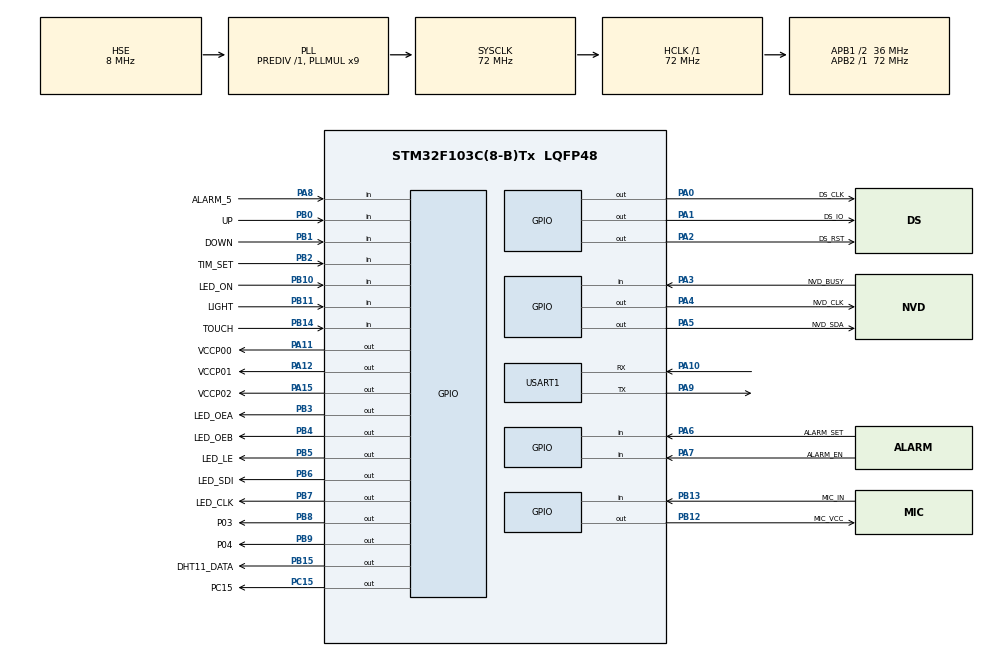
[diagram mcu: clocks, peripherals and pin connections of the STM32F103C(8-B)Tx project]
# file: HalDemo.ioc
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Mcu.Family=STM32F1
Mcu.Name=STM32F103C(8-B)Tx
Mcu.Package=LQFP48
NVIC.PriorityGroup=NVIC_PRIORITYGROUP_4
PA0-WKUP.GPIO_Label=DS_CLK
PA0-WKUP.GPIO_Speed=GPIO_SPEED_FREQ_HIGH
PA0-WKUP.Signal=GPIO_Output
PA1.GPIO_Label=DS_IO
PA1.GPIO_ModeDefaultOutputPP=GPIO_MODE_OUTPUT_OD
PA1.GPIO_PuPd=GPIO_NOPULL
PA1.GPIO_Speed=GPIO_SPEED_FREQ_HIGH
PA1.PinState=GPIO_PIN_SET
PA1.Signal=GPIO_Output
PA10.Mode=Asynchronous
PA10.Signal=USART1_RX
PA11.GPIO_Label=VCCP00
PA11.GPIO_Speed=GPIO_SPEED_FREQ_HIGH
PA11.PinState=GPIO_PIN_SET
PA11.Signal=GPIO_Output
PA12.GPIO_Label=VCCP01
PA12.GPIO_Speed=GPIO_SPEED_FREQ_HIGH
PA12.PinState=GPIO_PIN_SET
PA12.Signal=GPIO_Output
PA13.Mode=Serial_Wire
PA13.Signal=SYS_JTMS-SWDIO
PA14.Mode=Serial_Wire
PA14.Signal=SYS_JTCK-SWCLK
PA15.GPIO_Label=VCCP02
PA15.GPIO_Speed=GPIO_SPEED_FREQ_HIGH
PA15.PinState=GPIO_PIN_SET
PA15.Signal=GPIO_Output
PA2.GPIO_Label=DS_RST
PA2.GPIO_Speed=GPIO_SPEED_FREQ_HIGH
PA2.Signal=GPIO_Output
PA3.GPIO_Label=NVD_BUSY
PA3.GPIO_PuPd=GPIO_PULLUP
PA3.Signal=GPIO_Input
PA4.GPIO_Label=NVD_CLK
PA4.GPIO_PuPd=GPIO_NOPULL
PA4.GPIO_Speed=GPIO_SPEED_FREQ_HIGH
PA4.PinState=GPIO_PIN_SET
PA4.Signal=GPIO_Output
PA5.GPIO_Label=NVD_SDA
PA5.GPIO_Speed=GPIO_SPEED_FREQ_HIGH
PA5.PinState=GPIO_PIN_SET
PA5.Signal=GPIO_Output
PA6.GPIO_Label=ALARM_SET
PA6.GPIO_PuPd=GPIO_PULLUP
PA6.Signal=GPIO_Input
PA7.GPIO_Label=ALARM_EN
PA7.GPIO_PuPd=GPIO_PULLUP
PA7.Signal=GPIO_Input
PA8.GPIO_Label=ALARM_5
PA8.GPIO_PuPd=GPIO_PULLUP
PA8.Signal=GPIO_Input
PA9.Mode=Asynchronous
PA9.Signal=USART1_TX
PB0.GPIO_Label=UP
PB0.GPIO_PuPd=GPIO_PULLUP
PB0.Signal=GPIO_Input
PB1.GPIO_Label=DOWN
PB1.GPIO_PuPd=GPIO_PULLUP
PB1.Signal=GPIO_Input
PB10.GPIO_Label=LED_ON
PB10.GPIO_PuPd=GPIO_PULLUP
PB10.Signal=GPIO_Input
PB11.GPIO_Label=LIGHT
PB11.GPIO_PuPd=GPIO_PULLUP
PB11.Signal=GPIO_Input
PB12.GPIO_Label=MIC_VCC
PB12.PinState=GPIO_PIN_SET
PB12.Signal=GPIO_Output
PB13.GPIO_Label=MIC_IN
PB13.Signal=GPIO_Input
PB14.GPIO_Label=TOUCH
PB14.Signal=GPIO_Input
PB15.GPIO_Label=DHT11_DATA
PB15.GPIO_ModeDefaultOutputPP=GPIO_MODE_OUTPUT_OD
PB15.GPIO_PuPd=GPIO_NOPULL
PB15.GPIO_Speed=GPIO_SPEED_FREQ_HIGH
PB15.PinState=GPIO_PIN_SET
PB15.Signal=GPIO_Output
PB2.GPIO_Label=TIM_SET
PB2.GPIO_PuPd=GPIO_PULLUP
PB2.Signal=GPIO_Input
PB3.GPIO_Label=LED_OEA
PB3.GPIO_Speed=GPIO_SPEED_FREQ_HIGH
PB3.PinState=GPIO_PIN_SET
PB3.Signal=GPIO_Output
PB4.GPIO_Label=LED_OEB
PB4.GPIO_Speed=GPIO_SPEED_FREQ_HIGH
PB4.PinState=GPIO_PIN_SET
PB4.Signal=GPIO_Output
PB5.GPIO_Label=LED_LE
PB5.GPIO_Speed=GPIO_SPEED_FREQ_HIGH
PB5.PinState=GPIO_PIN_SET
PB5.Signal=GPIO_Output
PB6.GPIO_Label=LED_SDI
PB6.GPIO_Speed=GPIO_SPEED_FREQ_HIGH
PB6.PinState=GPIO_PIN_RESET
PB6.Signal=GPIO_Output
PB7.GPIO_Label=LED_CLK
PB7.GPIO_Speed=GPIO_SPEED_FREQ_HIGH
PB7.Signal=GPIO_Output
PB8.GPIO_Label=P03
PB8.GPIO_Speed=GPIO_SPEED_FREQ_HIGH
PB8.PinState=GPIO_PIN_SET
PB8.Signal=GPIO_Output
PB9.GPIO_Label=P04
PB9.GPIO_Speed=GPIO_SPEED_FREQ_HIGH
PB9.PinState=GPIO_PIN_SET
PB9.Signal=GPIO_Output
PC15-OSC32_OUT.GPIO_Label=PC15
PC15-OSC32_OUT.GPIO_Speed=GPIO_SPEED_FREQ_LOW
PC15-OSC32_OUT.PinState=GPIO_PIN_RESET
PC15-OSC32_OUT.Signal=GPIO_Output
PD0-OSC_IN.Mode=HSE-External-Oscillator
PD0-OSC_IN.Signal=RCC_OSC_IN
PD1-OSC_OUT.Mode=HSE-External-Oscillator
PD1-OSC_OUT.Signal=RCC_OSC_OUT
ProjectManager.HeapSize=0x200
ProjectManager.StackSize=0x400
ProjectManager.TargetToolchain=MDK-ARM V5.32
RCC.AHBFreq_Value=72000000
RCC.APB1CLKDivider=RCC_HCLK_DIV2
RCC.APB1Freq_Value=36000000
RCC.APB1TimFreq_Value=72000000
RCC.APB2Freq_Value=72000000
RCC.APB2TimFreq_Value=72000000
RCC.HCLKFreq_Value=72000000
RCC.PLLMUL=RCC_PLL_MUL9
RCC.PLLSourceVirtual=RCC_PLLSOURCE_HSE
RCC.SYSCLKFreq_VALUE=72000000
RCC.SYSCLKSource=RCC_SYSCLKSOURCE_PLLCLK
RCC.USBFreq_Value=72000000
USART1.VirtualMode=VM_ASYNC
board=custom

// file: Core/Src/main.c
/* USER CODE BEGIN Header */
/**
 ******************************************************************************
 * @file           : main.c
 * @brief          : Main program body
 ******************************************************************************
 * @attention
 *
 * Copyright (c) 2026 STMicroelectronics.
 * All rights reserved.
 *
 * This software is licensed under terms that can be found in the LICENSE file
 * in the root directory of this software component.
 * If no LICENSE file comes with this software, it is provided AS-IS.
 *
 ******************************************************************************
 */
/* USER CODE END Header */
#include "main.h"
#include "usart.h"
#include "gpio.h"

/* USER CODE BEGIN Includes */
#include "Com_debug.h"
#include "App_freeRTOS.h"
/* USER CODE END Includes */

void SystemClock_Config(void);

int main(void)
{

  /* MCU Configuration--------------------------------------------------------*/

  /* Reset of all peripherals, Initializes the Flash interface and the Systick. */
  HAL_Init();

  /* Configure the system clock */
  SystemClock_Config();

  /* Initialize all configured peripherals */
  MX_GPIO_Init();
  MX_USART1_UART_Init();
  /* USER CODE BEGIN 2 */
  //*******************************尽量在初始化后写代码************************************//
  // HAL_UART_Transmit(&huart1, "Hello World!\r\n", 14, 1000);

  // freeRTOS的启动函数
  App_freeRTOS_Start();
  /* USER CODE END 2 */

  /* Infinite loop */
  while (1)
  {

  }
}

void SystemClock_Config(void)
{
  RCC_OscInitTypeDef RCC_OscInitStruct = {0};
  RCC_ClkInitTypeDef RCC_ClkInitStruct = {0};

  /** Initializes the RCC Oscillators according to the specified parameters
  * in the RCC_OscInitTypeDef structure.
  */
  RCC_OscInitStruct.OscillatorType = RCC_OSCILLATORTYPE_HSE;
  RCC_OscInitStruct.HSEState = RCC_HSE_ON;
  RCC_OscInitStruct.HSEPredivValue = RCC_HSE_PREDIV_DIV1;
  RCC_OscInitStruct.HSIState = RCC_HSI_ON;
  RCC_OscInitStruct.PLL.PLLState = RCC_PLL_ON;
  RCC_OscInitStruct.PLL.PLLSource = RCC_PLLSOURCE_HSE;
  RCC_OscInitStruct.PLL.PLLMUL = RCC_PLL_MUL9;
  if (HAL_RCC_OscConfig(&RCC_OscInitStruct) != HAL_OK)
  {
    Error_Handler();
  }

  /** Initializes the CPU, AHB and APB buses clocks
  */
  RCC_ClkInitStruct.ClockType = RCC_CLOCKTYPE_HCLK|RCC_CLOCKTYPE_SYSCLK
                              |RCC_CLOCKTYPE_PCLK1|RCC_CLOCKTYPE_PCLK2;
  RCC_ClkInitStruct.SYSCLKSource = RCC_SYSCLKSOURCE_PLLCLK;
  RCC_ClkInitStruct.AHBCLKDivider = RCC_SYSCLK_DIV1;
  RCC_ClkInitStruct.APB1CLKDivider = RCC_HCLK_DIV2;
  RCC_ClkInitStruct.APB2CLKDivider = RCC_HCLK_DIV1;

  if (HAL_RCC_ClockConfig(&RCC_ClkInitStruct, FLASH_LATENCY_2) != HAL_OK)
  {
    Error_Handler();
  }
}

void Error_Handler(void)
{
  __disable_irq();
  while (1)
  {
  }
}
